# ATtiny861 register map
Vendor: Atmel
Registers are 8-bit, read-write, reset 0x0 unless marked. A register's access mark holds for its fields unless they carry their own. Offsets are from the block's base; lines under a group give offsets from that group; [hi:lo] are bit positions; {n}, {i} and the like mark numbered series; 'fields as' and 'values as' point back to an identical list; <NAME> marks a mode.

## Memory map
0x00000000 FUSE — Fuses
0x00000000 LOCKBIT — Lockbits
0x00000020 TC1 — Timer/Counter1, 10-bit
0x00000021 ADC — Analog-to-Digital Converter
0x00000028 AC — Analog Comparator
0x0000002A CPU — CPU Registers
0x0000002D USI — Universal Serial Interface
0x00000032 TC0 — Timer/Counter0
0x00000036 PORTB — I/O Port
0x00000039 PORTA — I/O Port
0x0000003C EEPROM
0x00000041 WDT — Watchdog Timer
0x00000042 EXINT — External Interrupts
0x00000057 BOOT_LOAD — Bootloader

## Interrupts
0 RESET (CPU) — External Reset, Power-on Reset and Watchdog Reset
1 INT0 (CPU) — External Interrupt 0
2 PCINT (CPU) — Pin Change Interrupt
3 TIMER1_COMPA (CPU) — Timer/Counter1 Compare Match 1A
4 TIMER1_COMPB (CPU) — Timer/Counter1 Compare Match 1B
5 TIMER1_OVF (CPU) — Timer/Counter1 Overflow
6 TIMER0_OVF (CPU) — Timer/Counter0 Overflow
7 USI_START (CPU)
8 USI_OVF (CPU) — USI Overflow
9 EE_RDY (CPU) — EEPROM Ready
10 ANA_COMP (CPU) — Analog Comparator
11 ADC (CPU) — ADC Conversion Complete
12 WDT (CPU) — Watchdog Time-Out
13 INT1 (CPU) — External Interrupt 1
14 TIMER0_COMPA (CPU) — Timer/Counter0 Compare Match A
15 TIMER0_COMPB (CPU) — Timer/Counter0 Compare Match B
16 TIMER0_CAPT (CPU) — ADC Conversion Complete
17 TIMER1_COMPD (CPU) — Timer/Counter1 Compare Match D
18 FAULT_PROTECTION (CPU) — Timer/Counter1 Fault Protection

## AC — Analog Comparator
Base 0x00000028
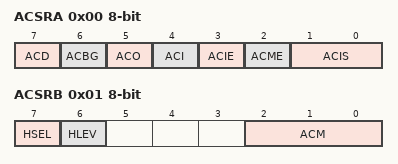
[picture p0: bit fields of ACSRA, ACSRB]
0x00 ACSRA — Analog Comparator Control And Status Register A
  [7] ACD — Analog Comparator Disable
  [6] ACBG — Analog Comparator Bandgap Select
  [5] ACO ro — Analog Compare Output
  [4] ACI — Analog Comparator Interrupt Flag
  [3] ACIE — Analog Comparator Interrupt Enable
  [2] ACME — Analog Comparator Multiplexer Enable
  [1:0] ACIS — Analog Comparator Interrupt Mode Select
    0=ON_TOGGLE (Interrupt on Toggle); 2=ON_FALLING_EDGE (Interrupt on Falling Edge); 3=ON_RISING_EDGE (Interrupt on Rising Edge)
0x01 ACSRB — Analog Comparator Control And Status Register B
  [7] HSEL — Hysteresis Select
  [6] HLEV — Hysteresis Level
  [2:0] ACM — Analog Comparator Multiplexer

## ADC — Analog-to-Digital Converter
Base 0x00000021
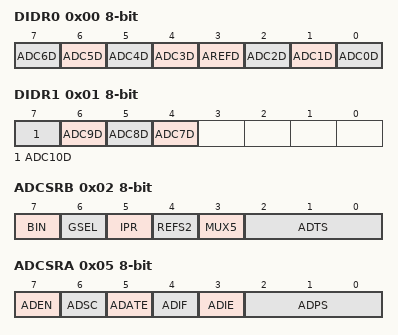
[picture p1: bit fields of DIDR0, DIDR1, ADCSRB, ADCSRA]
0x00 DIDR0 — Digital Input Disable Register 0
  [n+1] ADC{n}D (n=3..6) — ADC{n} Digital input Disable
  [3] AREFD — AREF Digital Input Disable
  [2] ADC2D — ADC2 Digital input Disable
  [1] ADC1D — ADC1 Digital input Disable
  [0] ADC0D — ADC0 Digital input Disable
0x01 DIDR1 — Digital Input Disable Register 1
  [n-3] ADC{n}D (n=7..10) — ADC{n} Digital input Disable
0x02 ADCSRB — ADC Control and Status Register B
  [7] BIN — Bipolar Input Mode
  [6] GSEL — Gain Select
  [5] IPR — Input Polarity Mode
  [4] REFS2 — Reference Selection Bit
  [3] MUX5 — Analog Channel and Gain Selection Bit 5
  [2:0] ADTS — ADC Auto Trigger Sources
    0=Free Running mode; 1=Analog Comparator; 2=External Interrupt Request 0; 3=Timer/Counter0 Compare Match A; 4=Timer/Counter0 Overflow; 5=Timer/Counter1 Compare Match B; 6=Timer/Counter1 Overflow; 7=Watchdog Interrupt Request
0x03 ADC 16-bit (reset mask 0xFF) — ADC Data Register Bytes
0x05 ADCSRA — The ADC Control and Status register
  [7] ADEN — ADC Enable
  [6] ADSC — ADC Start Conversion
  [5] ADATE — ADC Auto Trigger Enable
  [4] ADIF — ADC Interrupt Flag
  [3] ADIE — ADC Interrupt Enable
  [2:0] ADPS — ADC Prescaler Select Bits
    1=PRESCALER_2 (Prescaler Value 2); 2=PRESCALER_4 (Prescaler Value 4); 3=PRESCALER_8 (Prescaler Value 8); 4=PRESCALER_16 (Prescaler Value 16); 5=PRESCALER_32 (Prescaler Value 32); 6=PRESCALER_64 (Prescaler Value 64); 7=PRESCALER_128 (Prescaler Value 128)
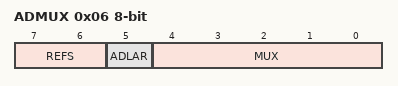
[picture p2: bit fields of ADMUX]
0x06 ADMUX — The ADC multiplexer Selection Register
  [7:6] REFS — Reference Selection Bits
    0=AREF (Aref Internal Vref turned off); 1=AVCC (AVcc with external capacitor at AREF pin); 3=INTERNAL (Internal 1.1V Voltage Reference with external capacitor at AREF pin)
  [5] ADLAR — Left Adjust Result
  [4:0] MUX — Analog Channel and Gain Selection Bits
